# AT32F421xx register map
Vendor: Keil; Series: AT32F421; File version: 1.0
CPU: CM4 r0p1, little endian, no MPU, FPU, 4 interrupt priority bits
Registers are 32-bit, read-write, reset 0x0 unless marked. A register's access mark holds for its fields unless they carry their own. Offsets are from the block's base; [hi:lo] are bit positions.

## IWDG — Independent watchdog
Base 0x40003000
0x00 KEY — Key register (IWDG_KEY)
  [15:0] KEY — Key value
0x04 PR — Prescaler register (IWDG_PR)
  [2:0] PR — Prescaler divider
0x08 RLD reset 0xFFF — Reload register (IWDG_RLR)
  [11:0] RLD — Watchdog counter reload value
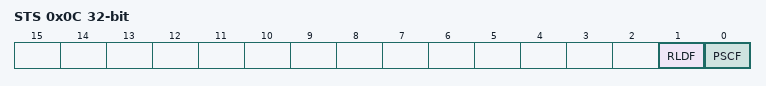
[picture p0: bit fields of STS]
0x0C STS ro — Status register (IWDG_SR)
  [1] RLDF — Watchdog counter reload value update
  [0] PSCF — Watchdog prescaler value update

## WWDG — Window watchdog
Base 0x40002C00
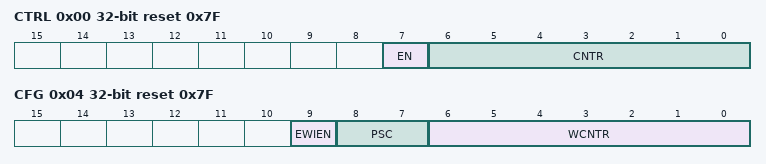
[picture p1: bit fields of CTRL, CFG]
0x00 CTRL reset 0x7F — Control register (WWDG_CR)
  [7] EN — Activation bit
  [6:0] CNTR — 7-bit counter (MSB to LSB)
0x04 CFG reset 0x7F — Configuration register (WWDG_CFG)
  [9] EWIEN — Early Wakeup Interrupt
  [8:7] PSC — Timer Base
  [6:0] WCNTR — 7-bit window value
0x08 STS — Status register (WWDG_SR)
  [0] EWIF — Early Wakeup Interrupt

## TMR6 — Basic timer
Base 0x40001000
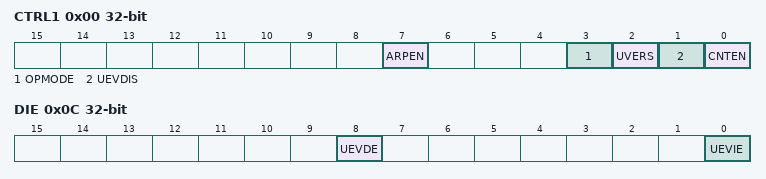
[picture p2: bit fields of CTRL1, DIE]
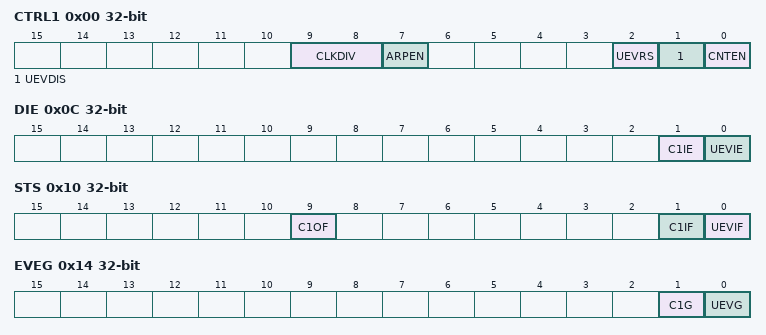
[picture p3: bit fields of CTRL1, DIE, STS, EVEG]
0x00 CTRL1 — control register 1
  [7] ARPEN — Auto-reload preload enable
  [3] OPMODE — One-pulse mode
  [2] UVERS — Update request source
  [1] UEVDIS — Update disable
  [0] CNTEN — Counter enable
0x04 CTRL2 — control register 2
  [6:4] MMSEL — Master mode selection
0x0C DIE — DMA/Interrupt enable register
  [8] UEVDE — Update DMA request enable
  [0] UEVIE — Update interrupt enable
0x10 STS — status register
  [0] UEVIF — Update interrupt flag
0x14 EVEG — event generation register
  [0] UEVG — Update generation
0x24 CNT — counter
  [15:0] CNT — Low counter value
0x28 DIV — prescaler
  [15:0] DIV — Prescaler value
0x2C AR — auto-reload register
  [15:0] AR — Low Auto-reload value

## TMR14 — General-purpose-timers
Base 0x40002000
0x00 CTRL1 — control register 1
  [9:8] CLKDIV — Clock division
  [7] ARPEN — Auto-reload preload enable
  [2] UEVRS — Update request source
  [1] UEVDIS — Update disable
  [0] CNTEN — Counter enable
0x0C DIE — DMA/Interrupt enable register
  [1] C1IE — Capture/Compare 1 interrupt enable
  [0] UEVIE — Update interrupt enable
0x10 STS — status register
  [9] C1OF — Capture/Compare 1 overcapture flag
  [1] C1IF — Capture/compare 1 interrupt flag
  [0] UEVIF — Update interrupt flag
0x14 EVEG wo — event generation register
  [1] C1G — Capture/compare 1 generation
  [0] UEVG — Update generation
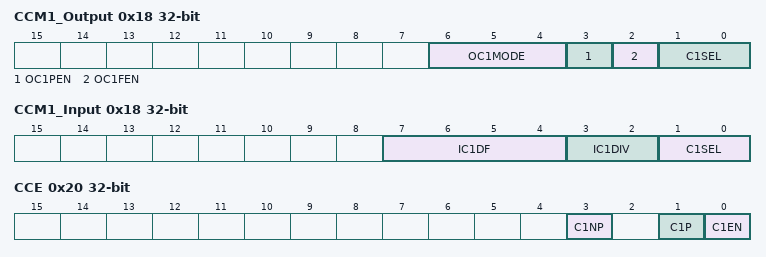
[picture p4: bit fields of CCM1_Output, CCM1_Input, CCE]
0x18 CCM1_Output — capture/compare mode register (output mode)
  [6:4] OC1MODE — Output Compare 1 mode
  [3] OC1PEN — Output Compare 1 preload enable
  [2] OC1FEN — Output compare 1 fast enable
  [1:0] C1SEL — Capture/Compare 1 selection
0x18 CCM1_Input (alternate view of CCM1_Output) — capture/compare mode register (input mode)
  [7:4] IC1DF — Input capture 1 filter
  [3:2] IC1DIV — Input capture 1 prescaler
  [1:0] C1SEL — Capture/Compare 1 selection
0x20 CCE — capture/compare enable register
  [3] C1NP — Capture/Compare 1 output Polarity
  [1] C1P — Capture/Compare 1 output Polarity
  [0] C1EN — Capture/Compare 1 output enable
0x24 CNT — counter
  [15:0] CNT — counter value
0x28 DIV — prescaler value
  [15:0] DIV — Prescaler value
0x2C AR — auto-reload register
  [15:0] AR — Auto-reload value
0x34 CC1 — capture/compare register 1
  [15:0] CC1 — Capture/Compare 1 value
0x50 RMP — Remap register
  [1:0] TI1_RMP — Timer input 1 remap

## TMR16 — General-purpose-timers
Base 0x40014400
Same registers: TMR17 0x40014800
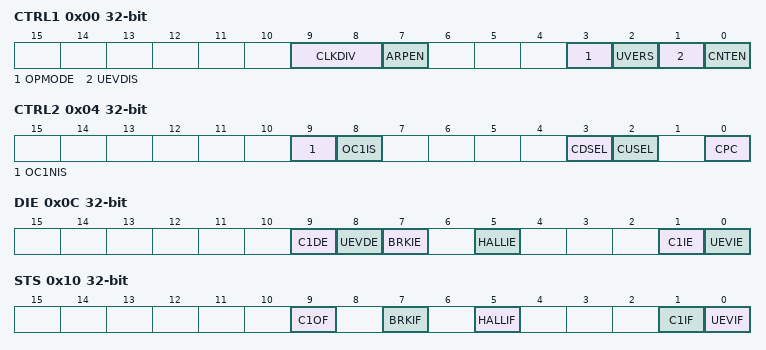
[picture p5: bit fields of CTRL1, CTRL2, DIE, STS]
0x00 CTRL1 — control register 1
  [9:8] CLKDIV — Clock division
  [7] ARPEN — Auto-reload preload enable
  [3] OPMODE — One-pulse mode
  [2] UVERS — Update request source
  [1] UEVDIS — Update disable
  [0] CNTEN — Counter enable
0x04 CTRL2 — control register 2
  [9] OC1NIS — Output Idle state 1
  [8] OC1IS — Output Idle state 1
  [3] CDSEL — Capture/compare DMA selection
  [2] CUSEL — Capture/compare control update selection
  [0] CPC — Capture/compare preloaded control
0x0C DIE — DMA/Interrupt enable register
  [9] C1DE — Capture/Compare 1 DMA request enable
  [8] UEVDE — Update DMA request enable
  [7] BRKIE — Break interrupt enable
  [5] HALLIE — COM interrupt enable
  [1] C1IE — Capture/Compare 1 interrupt enable
  [0] UEVIE — Update interrupt enable
0x10 STS — status register
  [9] C1OF — Capture/Compare 1 overcapture flag
  [7] BRKIF — Break interrupt flag
  [5] HALLIF — COM interrupt flag
  [1] C1IF — Capture/compare 1 interrupt flag
  [0] UEVIF — Update interrupt flag
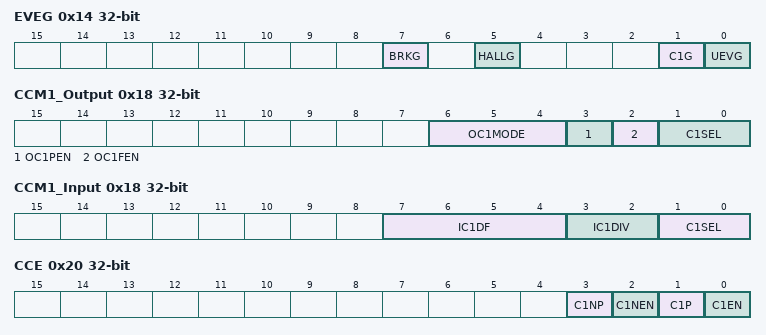
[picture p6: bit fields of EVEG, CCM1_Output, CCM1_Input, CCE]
0x14 EVEG wo — event generation register
  [7] BRKG — Break generation
  [5] HALLG — Capture/Compare control update generation
  [1] C1G — Capture/compare 1 generation
  [0] UEVG — Update generation
0x18 CCM1_Output — capture/compare mode register (output mode)
  [6:4] OC1MODE — Output Compare 1 mode
  [3] OC1PEN — Output Compare 1 preload enable
  [2] OC1FEN — Output Compare 1 fast enable
  [1:0] C1SEL — Capture/Compare 1 selection
0x18 CCM1_Input (alternate view of CCM1_Output) — capture/compare mode register 1 (input mode)
  [7:4] IC1DF — Input capture 1 filter
  [3:2] IC1DIV — Input capture 1 prescaler
  [1:0] C1SEL — Capture/Compare 1 selection
0x20 CCE — capture/compare enable register
  [3] C1NP — Capture/Compare 1 output Polarity
  [2] C1NEN — Capture/Compare 1 complementary output enable
  [1] C1P — Capture/Compare 1 output Polarity
  [0] C1EN — Capture/Compare 1 output enable
0x24 CNT — counter
  [15:0] CNT — counter value
0x28 DIV — prescaler value
  [15:0] DIV — Prescaler value
0x2C AR — auto-reload register
  [15:0] AR — Auto-reload value
0x30 RC — repetition counter register
  [7:0] RC — Repetition counter value
0x34 CC1 — capture/compare register 1
  [15:0] CC1 — Capture/Compare 1 value
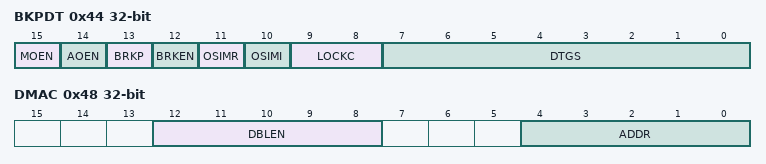
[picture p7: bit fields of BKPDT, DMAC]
0x44 BKPDT — break and dead-time register
  [15] MOEN — Main output enable
  [14] AOEN — Automatic output enable
  [13] BRKP — Break polarity
  [12] BRKEN — Break enable
  [11] OSIMR — Off-state selection for Run mode
  [10] OSIMI — Off-state selection for Idle mode
  [9:8] LOCKC — Lock configuration
  [7:0] DTGS — Dead-time generator setup
0x48 DMAC — DMA control register
  [12:8] DBLEN — DMA burst length
  [4:0] ADDR — DMA base address
0x4C DMABA — DMA address for full transfer
  [15:0] DMABA — DMA register for burst accesses
